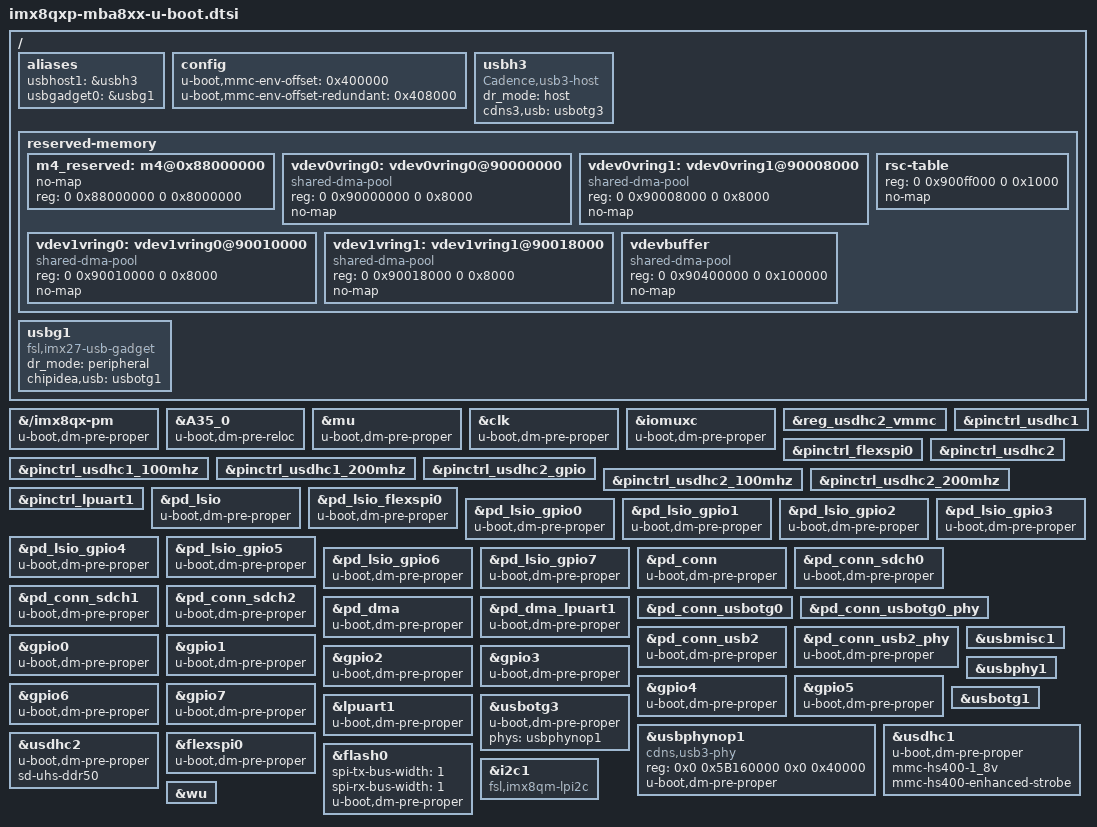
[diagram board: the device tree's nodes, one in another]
// SPDX-License-Identifier: GPL-2.0-or-later OR MIT
/*
 * Copyright 2018 - 2021 TQ-Systems GmbH
 */

/ {
	aliases {
		usbhost1 = &usbh3;
		usbgadget0 = &usbg1;
	};

	config {
		/* 32 kiB redundant env */
		u-boot,mmc-env-offset = <0x400000>;
		u-boot,mmc-env-offset-redundant = <0x408000>;
	};

	usbh3: usbh3 {
		compatible = "Cadence,usb3-host";
		dr_mode = "host";
		cdns3,usb = <&usbotg3>;
		status = "okay";
	};

	reserved-memory {
		/*
		 * 0x8800_0000 ~ 0x8FFF_FFFF is reserved for M4
		 * Should not be used at A core and Linux side, when M4 running
		 * from RAM. Needs to be the same as reserved in
		 * board_system_config of SCU FW
		 */
		m4_reserved: m4@0x88000000 {
			no-map;
			reg = <0 0x88000000 0 0x8000000>;
		};

		/*
		 * The region of 0x90000000 ... 0x90600000 is defined as
		 * shareable between CortexA and M4 in SCU FW alternative config
		 * the vdevring regions and the shared memory must be located
		 * in this region
		 * Needs to be adopted on a per project base
		 */
		vdev0vring0: vdev0vring0@90000000 {
			compatible = "shared-dma-pool";
			reg = <0 0x90000000 0 0x8000>;
			no-map;
		};

		vdev0vring1: vdev0vring1@90008000 {
			compatible = "shared-dma-pool";
			reg = <0 0x90008000 0 0x8000>;
			no-map;
		};

		vdev1vring0: vdev1vring0@90010000 {
			compatible = "shared-dma-pool";
			reg = <0 0x90010000 0 0x8000>;
			no-map;
		};

		vdev1vring1: vdev1vring1@90018000 {
			compatible = "shared-dma-pool";
			reg = <0 0x90018000 0 0x8000>;
			no-map;
		};

		rsc-table {
			reg = <0 0x900ff000 0 0x1000>;
			no-map;
		};

		vdevbuffer: vdevbuffer {
			compatible = "shared-dma-pool";
			reg = <0 0x90400000 0 0x100000>;
			no-map;
		};
	};

	usbg1: usbg1 {
		compatible = "fsl,imx27-usb-gadget";
		dr_mode = "peripheral";
		chipidea,usb = <&usbotg1>;
		status = "okay";
		u-boot,dm-spl;
	};
};

&{/imx8qx-pm} {
	u-boot,dm-pre-proper;
	u-boot,dm-spl;
};

&A35_0 {
	u-boot,dm-pre-reloc;
};

&mu {
	u-boot,dm-pre-proper;
	u-boot,dm-spl;
};

&clk {
	u-boot,dm-pre-proper;
	u-boot,dm-spl;
};

&iomuxc {
	u-boot,dm-pre-proper;
	u-boot,dm-spl;
};

&reg_usdhc2_vmmc {
	u-boot,dm-spl;
};

&pinctrl_flexspi0 {
	u-boot,dm-spl;
};

&pinctrl_usdhc1 {
	u-boot,dm-spl;
};

&pinctrl_usdhc1_100mhz {
	u-boot,dm-spl;
};

&pinctrl_usdhc1_200mhz {
	u-boot,dm-spl;
};

&pinctrl_usdhc2_gpio {
	u-boot,dm-spl;
};

&pinctrl_usdhc2 {
	u-boot,dm-spl;
};

&pinctrl_usdhc2_100mhz {
	u-boot,dm-spl;
};

&pinctrl_usdhc2_200mhz {
	u-boot,dm-spl;
};

&pinctrl_lpuart1 {
	u-boot,dm-spl;
};

&pd_lsio {
	u-boot,dm-pre-proper;
	u-boot,dm-spl;
};

&pd_lsio_flexspi0 {
	u-boot,dm-pre-proper;
	u-boot,dm-spl;
};

&pd_lsio_gpio0 {
	u-boot,dm-pre-proper;
	u-boot,dm-spl;
};

&pd_lsio_gpio1 {
	u-boot,dm-pre-proper;
	u-boot,dm-spl;
};

&pd_lsio_gpio2 {
	u-boot,dm-pre-proper;
	u-boot,dm-spl;
};

&pd_lsio_gpio3 {
	u-boot,dm-pre-proper;
	u-boot,dm-spl;
};

&pd_lsio_gpio4 {
	u-boot,dm-pre-proper;
	u-boot,dm-spl;
};

&pd_lsio_gpio5 {
	u-boot,dm-pre-proper;
	u-boot,dm-spl;
};

&pd_lsio_gpio6 {
	u-boot,dm-pre-proper;
	u-boot,dm-spl;
};

&pd_lsio_gpio7 {
	u-boot,dm-pre-proper;
	u-boot,dm-spl;
};

&pd_conn {
	u-boot,dm-pre-proper;
	u-boot,dm-spl;
};

&pd_conn_sdch0 {
	u-boot,dm-pre-proper;
	u-boot,dm-spl;
};

&pd_conn_sdch1 {
	u-boot,dm-pre-proper;
	u-boot,dm-spl;
};

&pd_conn_sdch2 {
	u-boot,dm-pre-proper;
	u-boot,dm-spl;
};

&pd_dma {
	u-boot,dm-pre-proper;
	u-boot,dm-spl;
};

&pd_dma_lpuart1 {
	u-boot,dm-pre-proper;
};

&pd_conn_usbotg0 {
	u-boot,dm-spl;
};

&pd_conn_usbotg0_phy {
	u-boot,dm-spl;
};

&pd_conn_usb2 {
	u-boot,dm-pre-proper;
	u-boot,dm-spl;
};

&pd_conn_usb2_phy {
	u-boot,dm-pre-proper;
	u-boot,dm-spl;
};

&gpio0 {
	u-boot,dm-pre-proper;
	u-boot,dm-spl;
};

&gpio1 {
	u-boot,dm-pre-proper;
	u-boot,dm-spl;
};

&gpio2 {
	u-boot,dm-pre-proper;
	u-boot,dm-spl;
};

&gpio3 {
	u-boot,dm-pre-proper;
	u-boot,dm-spl;
};

&gpio4 {
	u-boot,dm-pre-proper;
	u-boot,dm-spl;
};

&gpio5 {
	u-boot,dm-pre-proper;
	u-boot,dm-spl;
};

&gpio6 {
	u-boot,dm-pre-proper;
	u-boot,dm-spl;
};

&gpio7 {
	u-boot,dm-pre-proper;
	u-boot,dm-spl;
};

&lpuart1 {
	u-boot,dm-pre-proper;
	u-boot,dm-spl;
};

&usbmisc1 {
	u-boot,dm-spl;
};

&usbphy1 {
	u-boot,dm-spl;
};

&usbotg1 {
	u-boot,dm-spl;
};

&usbotg3 {
	u-boot,dm-pre-proper;
	phys = <&usbphynop1>;
};

&usbphynop1 {
	compatible = "cdns,usb3-phy";
	reg = <0x0 0x5B160000 0x0 0x40000>;
	#phy-cells = <0>;
	u-boot,dm-pre-proper;
};

&usdhc1 {
	u-boot,dm-spl;
	u-boot,dm-pre-proper;
	mmc-hs400-1_8v;
	mmc-hs400-enhanced-strobe;
	/*
	 * prevents voltage switch warn: driver will switch even at
	 * fixed voltage
	 */
	/delete-property/ vmmc-supply;
	/delete-property/ vqmmc-supply;
};

&usdhc2 {
	u-boot,dm-spl;
	u-boot,dm-pre-proper;
	sd-uhs-ddr50;
};

&flexspi0 {
	u-boot,dm-spl;
	u-boot,dm-pre-proper;
};

&flash0 {
	spi-tx-bus-width = <1>;
	spi-rx-bus-width = <1>;
	u-boot,dm-spl;
	u-boot,dm-pre-proper;
};

&i2c1 {
	compatible = "fsl,imx8qm-lpi2c", "fsl,imx-virt-i2c";
};

&wu {
	u-boot,dm-spl;
};
